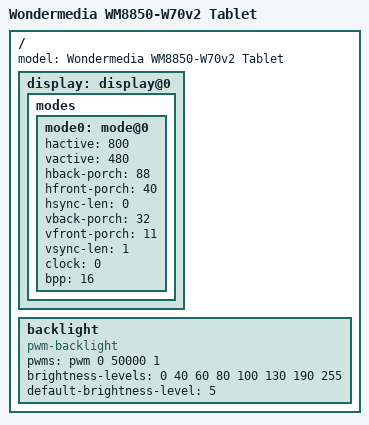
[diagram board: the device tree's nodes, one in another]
/*
 * wm8850-w70v2.dts
 *  - Device tree file for Wondermedia WM8850 Tablet
 *  - 'W70-V2' mainboard
 *  - HongLianYing 'HLY070ML268-21A' 7" LCD panel
 *
 * Copyright (C) 2012 Tony Prisk <linux@prisktech.co.nz>
 *
 * Licensed under GPLv2 or later
 */

/dts-v1/;
/include/ "wm8850.dtsi"

/ {
	model = "Wondermedia WM8850-W70v2 Tablet";

	/*
	 * Display node is based on Sascha Hauer's patch on dri-devel.
	 * Added a bpp property to calculate the size of the framebuffer
	 * until the binding is formalized.
	 */
	display: display@0 {
		modes {
			mode0: mode@0 {
				hactive = <800>;
				vactive = <480>;
				hback-porch = <88>;
				hfront-porch = <40>;
				hsync-len = <0>;
				vback-porch = <32>;
				vfront-porch = <11>;
				vsync-len = <1>;
				clock = <0>;	/* unused but required */
				bpp = <16>;	/* non-standard but required */
			};
		};
	};

	backlight {
		compatible = "pwm-backlight";
		pwms = <&pwm 0 50000 1>;	/* duty inverted */

		brightness-levels = <0 40 60 80 100 130 190 255>;
		default-brightness-level = <5>;
	};
};
